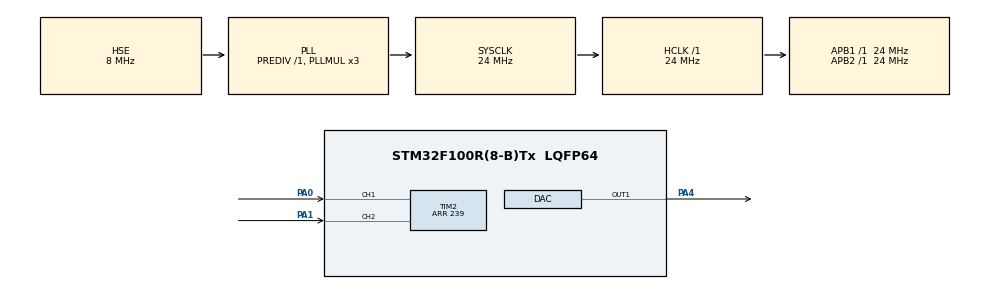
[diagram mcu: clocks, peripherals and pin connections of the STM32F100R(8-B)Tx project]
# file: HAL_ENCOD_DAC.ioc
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DAC.DAC_Trigger=DAC_TRIGGER_T6_TRGO
Dma.DAC_CH1.0.Direction=DMA_MEMORY_TO_PERIPH
Dma.DAC_CH1.0.Instance=DMA1_Channel3
Dma.DAC_CH1.0.MemDataAlignment=DMA_MDATAALIGN_HALFWORD
Dma.DAC_CH1.0.MemInc=DMA_MINC_ENABLE
Dma.DAC_CH1.0.Mode=DMA_CIRCULAR
Dma.DAC_CH1.0.PeriphDataAlignment=DMA_PDATAALIGN_HALFWORD
Dma.DAC_CH1.0.PeriphInc=DMA_PINC_DISABLE
Dma.DAC_CH1.0.Priority=DMA_PRIORITY_LOW
Dma.Request0=DAC_CH1
Mcu.Family=STM32F1
Mcu.Name=STM32F100R(8-B)Tx
Mcu.Package=LQFP64
NVIC.DMA1_Channel3_IRQn=true\:0\:0\:false\:false\:true\:false\:true
NVIC.PriorityGroup=NVIC_PRIORITYGROUP_4
NVIC.TIM6_DAC_IRQn=true\:0\:0\:false\:false\:true\:true\:true
PA0-WKUP.GPIO_PuPd=GPIO_PULLUP
PA0-WKUP.Signal=S_TIM2_CH1_ETR
PA1.GPIO_PuPd=GPIO_PULLUP
PA1.Signal=S_TIM2_CH2
PA13.Mode=Serial_Wire
PA13.Signal=SYS_JTMS-SWDIO
PA14.Mode=Serial_Wire
PA14.Signal=SYS_JTCK-SWCLK
PA4.Signal=COMP_DAC1_group
PD0-OSC_IN.Mode=HSE-External-Oscillator
PD0-OSC_IN.Signal=RCC_OSC_IN
PD1-OSC_OUT.Mode=HSE-External-Oscillator
PD1-OSC_OUT.Signal=RCC_OSC_OUT
ProjectManager.HeapSize=0x200
ProjectManager.StackSize=0x400
ProjectManager.TargetToolchain=EWARM V8.32
RCC.AHBFreq_Value=24000000
RCC.APB1Freq_Value=24000000
RCC.APB1TimFreq_Value=24000000
RCC.APB2Freq_Value=24000000
RCC.APB2TimFreq_Value=24000000
RCC.HCLKFreq_Value=24000000
RCC.PLLMUL=RCC_PLL_MUL3
RCC.PLLSource=RCC_PLLSOURCE_HSE
RCC.SYSCLKFreq_VALUE=24000000
RCC.SYSCLKSource=RCC_SYSCLKSOURCE_PLLCLK
SH.COMP_DAC1_group.0=DAC_OUT1,DAC_OUT1
SH.S_TIM2_CH1_ETR.0=TIM2_CH1,Encoder_Interface
SH.S_TIM2_CH2.0=TIM2_CH2,Encoder_Interface
TIM2.IC1Polarity=TIM_ICPOLARITY_FALLING
TIM2.IC2Polarity=TIM_ICPOLARITY_FALLING
TIM2.Period=239
TIM6.Period=239
TIM6.TIM_MasterOutputTrigger=TIM_TRGO_UPDATE
VP_TIM6_VS_ClockSourceINT.Mode=Enable_Timer
board=custom

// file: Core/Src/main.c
/* USER CODE BEGIN Header */
/**
  ******************************************************************************
  * @file           : main.c
  * @brief          : Main program body
  ******************************************************************************
  * @attention
  *
  * Copyright (c) 2024 STMicroelectronics.
  * All rights reserved.
  *
  * This software is licensed under terms that can be found in the LICENSE file
  * in the root directory of this software component.
  * If no LICENSE file comes with this software, it is provided AS-IS.
  *
  ******************************************************************************
  */
/* USER CODE END Header */
#include "main.h"

/* USER CODE BEGIN Includes */

#include "math.h"

/* USER CODE END Includes */

/* USER CODE BEGIN PTD */

#define PI 3.14159259
#define array_value 255

/* USER CODE END PTD */

DAC_HandleTypeDef hdac;
DMA_HandleTypeDef hdma_dac_ch1;

TIM_HandleTypeDef htim2;
TIM_HandleTypeDef htim6;

void SystemClock_Config(void);
static void MX_GPIO_Init(void);
static void MX_DMA_Init(void);
static void MX_DAC_Init(void);
static void MX_TIM6_Init(void);
static void MX_TIM2_Init(void);

/* USER CODE BEGIN 0 */

uint16_t counter;

uint16_t sine_value[array_value];

//uint32_t Etalon_value = 512;

uint32_t counter_encoder = 512;

//uint32_t Encoder = 0;

uint16_t Amplitude_sin = 512;

float Coef_Pow_Sin = 0.95f; //Коэф-т заглушение синусойды (заглушена на 5%)

  void Sinys (unsigned int Amplitude_sin)
  {
    for (counter=0; counter<array_value; counter++)
    {
      float sinysoida = sin(counter*2*PI/array_value);      //  float sinysoida = (((sin(counter*2*PI/array_value)+1)*0.7)*Amplitude_sin);

      sinysoida *= Coef_Pow_Sin;
      sinysoida *= Amplitude_sin; //4096/2
      sinysoida += ((4096/2)); // 4096/2 Насколько мы поднимаем наш сигнал

//
//      sinysoida += 1;
//
//      sinysoida *= Coef_Pow_Sin;
//

      sine_value[counter] = (uint16_t)sinysoida;
    }
  }

/* USER CODE END 0 */

int main(void)
{

  /* MCU Configuration--------------------------------------------------------*/

  /* Reset of all peripherals, Initializes the Flash interface and the Systick. */
  HAL_Init();

  /* Configure the system clock */
  SystemClock_Config();

  /* Initialize all configured peripherals */
  MX_GPIO_Init();
  MX_DMA_Init();
  MX_DAC_Init();
  MX_TIM6_Init();
  MX_TIM2_Init();
  /* USER CODE BEGIN 2 */

 Sinys (Amplitude_sin);
 HAL_DAC_Start_DMA(&hdac, DAC1_CHANNEL_1, (uint32_t *)sine_value, array_value, DAC_ALIGN_12B_R);
 HAL_TIM_Base_Start(&htim6);
 HAL_TIM_Encoder_Start(&htim2, TIM_CHANNEL_ALL);
 TIM2 -> CNT = 512;

  /* USER CODE END 2 */

  /* Infinite loop */
  /* USER CODE BEGIN WHILE */
  while (1)
  {
    counter_encoder = TIM2 -> CNT;

   if (TIM2 -> CNT < Amplitude_sin)
   {
     if (Amplitude_sin <= 512)
     {
       TIM2 -> CNT = 512;
     }
     else
     {
       Amplitude_sin = (TIM2 -> CNT) - 32;
        TIM2->CNT = Amplitude_sin;
     }
   }

   else if (TIM2 -> CNT > Amplitude_sin)
   {
     if (Amplitude_sin >= 2048)
     {
       TIM2 -> CNT = 2048;
     }
     else
     {
       Amplitude_sin = (TIM2 -> CNT) + 32;
       TIM2->CNT = Amplitude_sin;
     }
   }

   else
   {
      TIM2->CNT = Amplitude_sin;
   }

   Sinys(Amplitude_sin);

    /* USER CODE END WHILE */

  }
}

void SystemClock_Config(void)
{
  RCC_OscInitTypeDef RCC_OscInitStruct = {0};
  RCC_ClkInitTypeDef RCC_ClkInitStruct = {0};

  /** Initializes the RCC Oscillators according to the specified parameters
  * in the RCC_OscInitTypeDef structure.
  */
  RCC_OscInitStruct.OscillatorType = RCC_OSCILLATORTYPE_HSE;
  RCC_OscInitStruct.HSEState = RCC_HSE_ON;
  RCC_OscInitStruct.HSEPredivValue = RCC_HSE_PREDIV_DIV1;
  RCC_OscInitStruct.PLL.PLLState = RCC_PLL_ON;
  RCC_OscInitStruct.PLL.PLLSource = RCC_PLLSOURCE_HSE;
  RCC_OscInitStruct.PLL.PLLMUL = RCC_PLL_MUL3;
  if (HAL_RCC_OscConfig(&RCC_OscInitStruct) != HAL_OK)
  {
    Error_Handler();
  }
  /** Initializes the CPU, AHB and APB buses clocks
  */
  RCC_ClkInitStruct.ClockType = RCC_CLOCKTYPE_HCLK|RCC_CLOCKTYPE_SYSCLK
                              |RCC_CLOCKTYPE_PCLK1|RCC_CLOCKTYPE_PCLK2;
  RCC_ClkInitStruct.SYSCLKSource = RCC_SYSCLKSOURCE_PLLCLK;
  RCC_ClkInitStruct.AHBCLKDivider = RCC_SYSCLK_DIV1;
  RCC_ClkInitStruct.APB1CLKDivider = RCC_HCLK_DIV1;
  RCC_ClkInitStruct.APB2CLKDivider = RCC_HCLK_DIV1;

  if (HAL_RCC_ClockConfig(&RCC_ClkInitStruct, FLASH_LATENCY_0) != HAL_OK)
  {
    Error_Handler();
  }
}

static void MX_DAC_Init(void)
{

  DAC_ChannelConfTypeDef sConfig = {0};

  /** DAC Initialization
  */
  hdac.Instance = DAC;
  if (HAL_DAC_Init(&hdac) != HAL_OK)
  {
    Error_Handler();
  }
  /** DAC channel OUT1 config
  */
  sConfig.DAC_Trigger = DAC_TRIGGER_T6_TRGO;
  sConfig.DAC_OutputBuffer = DAC_OUTPUTBUFFER_ENABLE;
  if (HAL_DAC_ConfigChannel(&hdac, &sConfig, DAC_CHANNEL_1) != HAL_OK)
  {
    Error_Handler();
  }

}

static void MX_TIM2_Init(void)
{

  TIM_Encoder_InitTypeDef sConfig = {0};
  TIM_MasterConfigTypeDef sMasterConfig = {0};

  htim2.Instance = TIM2;
  htim2.Init.Prescaler = 0;
  htim2.Init.CounterMode = TIM_COUNTERMODE_UP;
  htim2.Init.Period = 239;
  htim2.Init.ClockDivision = TIM_CLOCKDIVISION_DIV1;
  htim2.Init.AutoReloadPreload = TIM_AUTORELOAD_PRELOAD_DISABLE;
  sConfig.EncoderMode = TIM_ENCODERMODE_TI1;
  sConfig.IC1Polarity = TIM_ICPOLARITY_FALLING;
  sConfig.IC1Selection = TIM_ICSELECTION_DIRECTTI;
  sConfig.IC1Prescaler = TIM_ICPSC_DIV1;
  sConfig.IC1Filter = 0;
  sConfig.IC2Polarity = TIM_ICPOLARITY_FALLING;
  sConfig.IC2Selection = TIM_ICSELECTION_DIRECTTI;
  sConfig.IC2Prescaler = TIM_ICPSC_DIV1;
  sConfig.IC2Filter = 0;
  if (HAL_TIM_Encoder_Init(&htim2, &sConfig) != HAL_OK)
  {
    Error_Handler();
  }
  sMasterConfig.MasterOutputTrigger = TIM_TRGO_RESET;
  sMasterConfig.MasterSlaveMode = TIM_MASTERSLAVEMODE_DISABLE;
  if (HAL_TIMEx_MasterConfigSynchronization(&htim2, &sMasterConfig) != HAL_OK)
  {
    Error_Handler();
  }

}

static void MX_TIM6_Init(void)
{

  TIM_MasterConfigTypeDef sMasterConfig = {0};

  htim6.Instance = TIM6;
  htim6.Init.Prescaler = 0;
  htim6.Init.CounterMode = TIM_COUNTERMODE_UP;
  htim6.Init.Period = 239;
  htim6.Init.AutoReloadPreload = TIM_AUTORELOAD_PRELOAD_DISABLE;
  if (HAL_TIM_Base_Init(&htim6) != HAL_OK)
  {
    Error_Handler();
  }
  sMasterConfig.MasterOutputTrigger = TIM_TRGO_UPDATE;
  sMasterConfig.MasterSlaveMode = TIM_MASTERSLAVEMODE_DISABLE;
  if (HAL_TIMEx_MasterConfigSynchronization(&htim6, &sMasterConfig) != HAL_OK)
  {
    Error_Handler();
  }

}

static void MX_DMA_Init(void)
{

  /* DMA controller clock enable */
  __HAL_RCC_DMA1_CLK_ENABLE();

  /* DMA interrupt init */
  /* DMA1_Channel3_IRQn interrupt configuration */
  HAL_NVIC_SetPriority(DMA1_Channel3_IRQn, 0, 0);
  HAL_NVIC_EnableIRQ(DMA1_Channel3_IRQn);

}

static void MX_GPIO_Init(void)
{

  /* GPIO Ports Clock Enable */
  __HAL_RCC_GPIOD_CLK_ENABLE();
  __HAL_RCC_GPIOA_CLK_ENABLE();

}

void Error_Handler(void)
{
  __disable_irq();
  while (1)
  {
  }
}
